# SN32F240 register map
Vendor: SONiX Technology Co., Ltd.; Series: SN32F200; File version: 2.0
CPU: CM0 r0p0, little endian, no MPU, no FPU, 2 interrupt priority bits
Registers are 32-bit, read-write, reset 0x0 unless marked. A register's access mark holds for its fields unless they carry their own. Offsets are from the block's base; [hi:lo] are bit positions; {n}, {i} and the like mark numbered series.

## SN_USB — Universal Serial Bus Full Speed Device Interface (USB)
Base 0x4005C000
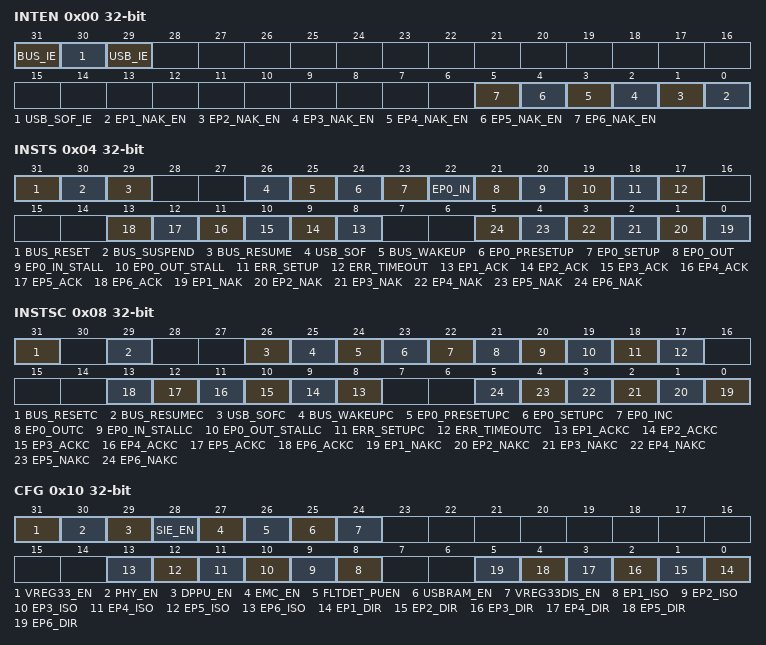
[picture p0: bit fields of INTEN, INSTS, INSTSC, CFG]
0x00 INTEN (reset mask 0xE0000003F) — Offset:0x00 USB Interrupt Enable Register
  [31] BUS_IE — Bus Event Interrupt Enable
    0=Disable BUS event interrupt; 1=Enable Bus event interrupt
  [30] USB_SOF_IE — USB SOF Interrupt Enable
    0=Disable USB SOF interrupt; 1=Enable USB SOF interrupt
  [29] USB_IE — USB Event Interrupt Enable
    0=Disable USB event interrupt; 1=Enable USB event interrupt
  [n-1] EP{n}_NAK_EN (n=1..6) — EP{n} NAK Interrupt Enable
    0=Disable EP{n} NAK interrupt function; 1=Enable EP{n} NAK interrupt function
0x04 INSTS ro (reset mask 0xE4FE3F3F) — Offset:0x04 USB Interrupt Event Status Register
  [31] BUS_RESET — USB Bus Reset signal flag
    0=No bus reset signal is detected; 1=Bus reset signal is detected
  [30] BUS_SUSPEND — USB Bus Suspend signal flag
    0=No bus suspend is detected; 1=Bus suspend is detected
  [29] BUS_RESUME — USB Bus Resume signal flag
    0=No bus resume signal is detected; 1=Bus resume signal from suspend mode is detected
  [26] USB_SOF — USB SOF packet received flag
    0=No USB SOF packet; 1=USB SOF packet is received
  [25] BUS_WAKEUP — Bus Wakeup Flag
    0=No wakeup from suspend mode; 1=Wakeup from suspend mode
  [24] EP0_PRESETUP — EP0 Setup Token Packet Flag
    0=No EP0 Setup token packet; 1=EP0 Setup token packet is received
  [23] EP0_SETUP — EP0 Setup Transaction Flag
    0=No EP0 Setup transaction; 1=EP0 Setup transaction is completed
  [22] EP0_IN — EP0 IN ACK Transaction Flag
    0=No EP0 IN Transaction; 1=EP0 IN Transaction is completed
  [21] EP0_OUT — EP0 OUT ACK Transaction Flag
    0=No EP0 OUT ACK transaction; 1=EP0 OUT ACK transaction is completed
  [20] EP0_IN_STALL — EP0 IN STALL Transaction is completed
    0=No EP0 IN STALL transaction; 1=EP0 IN STALL transaction is completed
  [19] EP0_OUT_STALL — EP0 OUT STALL transaction
    0=No EP0 OUT STALL transaction; 1=EP0 OUT STALL transaction is completed
  [18] ERR_SETUP — Wrong Setup data received
    0=Normal 8-byte Setup DATA0 is received; 1=Setup data is not 8-byte or is not DATA0
  [17] ERR_TIMEOUT — Timeout Status
    0=No time out; 1=Bus no any response more than 18 bits time
  [n+7] EP{n}_ACK (n=1..6) — Endpoint {n} ACK transaction flag
    0=No EP{n} ACK transacation; 1=EP{n} ACK transaction completes
  [n-1] EP{n}_NAK (n=1..6) — Endpoint {n} NAK transaction flag
    0=No EP{n} NAK transacation; 1=EP{n} NAK transaction completes
0x08 INSTSC wo (reset mask 0xA4FE3F3F) — Offset:0x08 USB Interrupt Event Status Clear Register
  [31] BUS_RESETC — USB Bus Reset clear bit
    0=No effect; 1=Clear BUS_RESET bit
  [29] BUS_RESUMEC — USB Bus Resume clear bit
    0=No effect; 1=Clear BUS_RESUME bit
  [26] USB_SOFC — USB SOF clear bit
    0=No effect; 1=Clear USB_SOF bit
  [25] BUS_WAKEUPC — Bus Wakeup clear bit
    0=No effect; 1=Clear BUS_WAKEUP bit
  [24] EP0_PRESETUPC — EP0 PRESETUP clear bit
    0=No effect; 1=Clear EP0_PRESETUP bit
  [23] EP0_SETUPC — EP0 SETUP clear bit
    0=No effect; 1=Clear EP0_SETUP bit
  [22] EP0_INC — EP0 IN clear bit
    0=No effect; 1=Clear EP0_IN bit
  [21] EP0_OUTC — EP0 OUT clear bit
    0=No effect; 1=Clear EP0_OUT bit
  [20] EP0_IN_STALLC — EP0 IN STALL clear bit
    0=No effect; 1=Clear EP0_IN_STALL bit
  [19] EP0_OUT_STALLC — EP0 OUT STALL clear bit
    0=No effect; 1=Clear EP0_OUT_STALL bit
  [18] ERR_SETUPC — Error Setup clear bit
    0=No effect; 1=Clear ERR_SETUP bit
  [17] ERR_TIMEOUTC — Timeout Error clear bit
    0=No effect; 1=Clear ERR_TIMEOUT bit
  [n+7] EP{n}_ACKC (n=1..6) — EP{n} ACK clear bit
    0=No effect; 1=Clear EP{n}_ACK bit
  [n-1] EP{n}_NAKC (n=1..6) — EP{n} NAK clear bit
    0=No effect; 1=Clear EP{n}_NAK bit
0x0C ADDR — Offset:0x0C USB Device Address Register
  [6:0] UADDR — USB device's address
0x10 CFG — Offset:0x10 USB Configuration Register
  [31] VREG33_EN — Enable the internal VREG33 ouput
    0=Disable VREG33 ouput; 1=Enable VREG33 ouput
  [30] PHY_EN — PHY Transceiver Function Enable
    0=Disable PHY transceiver function; 1=Enable PHY transceiver function
  [29] DPPU_EN — Enable internal D+ 1.5k pull-up resistor
    0=Disable internal D+ pull-up resistor; 1=Enable internal D+ pull-up resistor
  [28] SIE_EN — USB Serial Interface Engine Enable
    0=Disable USB SIE function; 1=Enable USB SIE function
  [27] EMC_EN — Enable USB EMC protection
    0=Disable EMC protection; 1=Enable EMC protection
  [26] FLTDET_PUEN — Enable internal D+ and D- weak pull-up resistor
    0=Enable; 1=Disable
  [25] USBRAM_EN — Enable USB 512-byte RAM function
    0=Disable; 1=Enable
  [24] VREG33DIS_EN — Enable 400ohm discharge path of VREG33 to GND
    0=Disable; 1=Enable
  [n+7] EP{n}_ISO (n=1..6) — Endpoint {n} ISO mode setting
    0=Enable Interrupt/Bulk mode; 1=Enable ISO mode
  [n-1] EP{n}_DIR (n=1..6) — Endpoint {n} IN/OUT direction setting
    0=IN (EP{n} only handshakes to IN token packet); 1=OUT (EP{n} only handshakes to OUT token packet)
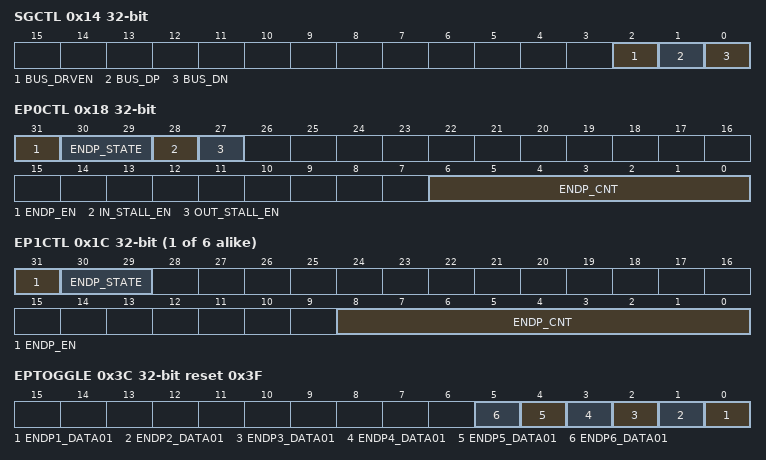
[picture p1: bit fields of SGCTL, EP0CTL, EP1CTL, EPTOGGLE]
0x14 SGCTL — Offset:0x14 USB Signal Control Register
  [2] BUS_DRVEN — Enable to drive USB bus
    0=Disable (Not to drive USB bus); 1=Enable (Drive USB bus)
  [1] BUS_DP — USB DP state
    0=Low (D+ state is low); 1=High (D+ state is high)
  [0] BUS_DN — USB D- state
    0=Low (D- state is low); 1=High (D- state is high)
0x18 EP0CTL (reset mask 0xF000000F) — Offset:0x18 USB Endpoint 0 Control Register
  [31] ENDP_EN — Enable Endpoint 0 Function
    0=Disable; 1=Enable
  [30:29] ENDP_STATE — Endpoint Handshake State
    0=NAK; 1=ACK; 2=INOUT_STALL; 3=INOUT_STALL
  [28] IN_STALL_EN — Enable EP0 IN STALL handshake
    0=Disable; 1=Enable
  [27] OUT_STALL_EN — Enable EP0 OUT STALL handshake
    0=Disable; 1=Enable
  [6:0] ENDP_CNT — Endpoint byte count
{0x18+4i} EP{i}CTL (i=1..6) — Offset:{0x18+4i} USB Endpoint {i} Control Register
  [31] ENDP_EN — Endpoint {i} Function enable bit
    0=Disable; 1=Enable
  [30:29] ENDP_STATE — Endpoint Handshake State
    0=NAK; 1=ACK; 2=STALL; 3=STALL
  [8:0] ENDP_CNT — Endpoint byte count
0x3C EPTOGGLE reset 0x3F — Offset:0x3C USB Endpoint Data Toggle Register
  [n-1] ENDP{n}_DATA01 (n=1..6) — Endpoint {n} data toggle bit
    0=Disable (Clear EP{n} toggle bit to DATA0); 1=Toggle (HW sets toggle bit automatically)
{0x44+4i} EP{i}BUFOS (i=1..6) — Offset:{0x44+4i} USB Endpoint {i} Buffer Offset Register
  [8:2] OFFSET — The offset address for endpoint data buffer
0x60 FRMNO ro — Offset:0x60 USB Frame Number Register
  [10:0] FRAME_NO rw — The 11-bit frame number of the SOF packet
0x64 PHYPRM — Offset:0x64 USB PHY Parameter Register
  [31:26] PHY_PARAM — The USB PHY parameter value
0x100 SRAM — Offset:0x100 USB SRAM starting address
